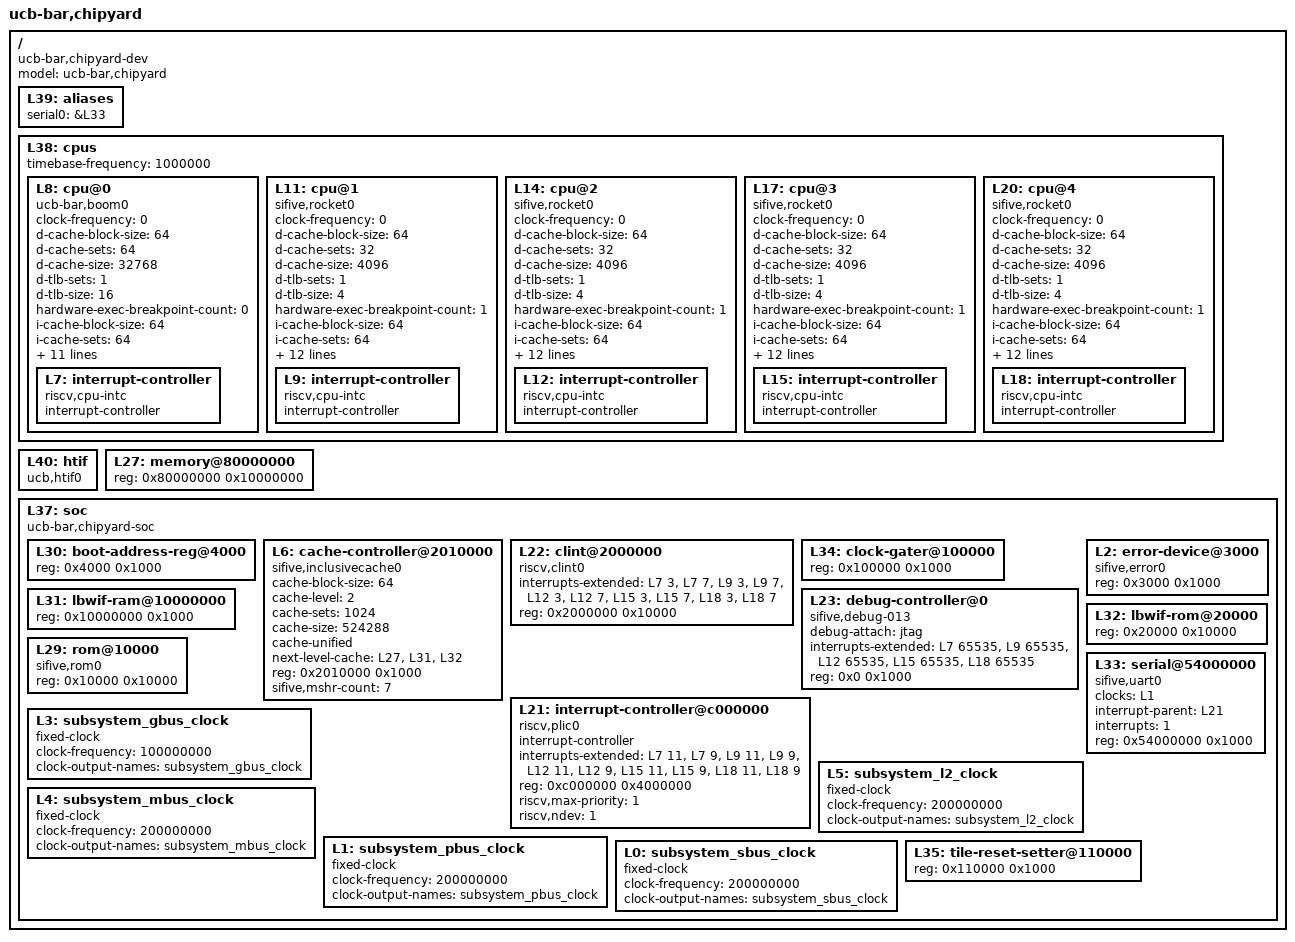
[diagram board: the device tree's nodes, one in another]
/dts-v1/;

/ {
	#address-cells = <1>;
	#size-cells = <1>;
	compatible = "ucb-bar,chipyard-dev";
	model = "ucb-bar,chipyard";
	L39: aliases {
		serial0 = &L33;
	};
	L38: cpus {
		#address-cells = <1>;
		#size-cells = <0>;
		timebase-frequency = <1000000>;
		L8: cpu@0 {
			clock-frequency = <0>;
			compatible = "ucb-bar,boom0", "riscv";
			d-cache-block-size = <64>;
			d-cache-sets = <64>;
			d-cache-size = <32768>;
			d-tlb-sets = <1>;
			d-tlb-size = <16>;
			device_type = "cpu";
			hardware-exec-breakpoint-count = <0>;
			i-cache-block-size = <64>;
			i-cache-sets = <64>;
			i-cache-size = <32768>;
			i-tlb-sets = <1>;
			i-tlb-size = <32>;
			mmu-type = "riscv,sv39";
			next-level-cache = <&L6>;
			reg = <0x0>;
			riscv,isa = "rv64imafdcZicsr_Zifencei_Zihpm";
			riscv,pmpgranularity = <4>;
			riscv,pmpregions = <8>;
			status = "okay";
			timebase-frequency = <1000000>;
			tlb-split;
			L7: interrupt-controller {
				#interrupt-cells = <1>;
				compatible = "riscv,cpu-intc";
				interrupt-controller;
			};
		};
		L11: cpu@1 {
			clock-frequency = <0>;
			compatible = "sifive,rocket0", "riscv";
			d-cache-block-size = <64>;
			d-cache-sets = <32>;
			d-cache-size = <4096>;
			d-tlb-sets = <1>;
			d-tlb-size = <4>;
			device_type = "cpu";
			hardware-exec-breakpoint-count = <1>;
			i-cache-block-size = <64>;
			i-cache-sets = <64>;
			i-cache-size = <32768>;
			i-tlb-sets = <1>;
			i-tlb-size = <32>;
			mmu-type = "riscv,sv39";
			next-level-cache = <&L6>;
			reg = <0x1>;
			riscv,isa = "rv64imafdcZicsr_Zifencei_Zihpm_Xrocket";
			riscv,pmpgranularity = <4>;
			riscv,pmpregions = <8>;
			status = "okay";
			timebase-frequency = <1000000>;
			tlb-split;
			L9: interrupt-controller {
				#interrupt-cells = <1>;
				compatible = "riscv,cpu-intc";
				interrupt-controller;
			};
		};
		L14: cpu@2 {
			clock-frequency = <0>;
			compatible = "sifive,rocket0", "riscv";
			d-cache-block-size = <64>;
			d-cache-sets = <32>;
			d-cache-size = <4096>;
			d-tlb-sets = <1>;
			d-tlb-size = <4>;
			device_type = "cpu";
			hardware-exec-breakpoint-count = <1>;
			i-cache-block-size = <64>;
			i-cache-sets = <64>;
			i-cache-size = <32768>;
			i-tlb-sets = <1>;
			i-tlb-size = <32>;
			mmu-type = "riscv,sv39";
			next-level-cache = <&L6>;
			reg = <0x2>;
			riscv,isa = "rv64imafdcZicsr_Zifencei_Zihpm_Xrocket";
			riscv,pmpgranularity = <4>;
			riscv,pmpregions = <8>;
			status = "okay";
			timebase-frequency = <1000000>;
			tlb-split;
			L12: interrupt-controller {
				#interrupt-cells = <1>;
				compatible = "riscv,cpu-intc";
				interrupt-controller;
			};
		};
		L17: cpu@3 {
			clock-frequency = <0>;
			compatible = "sifive,rocket0", "riscv";
			d-cache-block-size = <64>;
			d-cache-sets = <32>;
			d-cache-size = <4096>;
			d-tlb-sets = <1>;
			d-tlb-size = <4>;
			device_type = "cpu";
			hardware-exec-breakpoint-count = <1>;
			i-cache-block-size = <64>;
			i-cache-sets = <64>;
			i-cache-size = <32768>;
			i-tlb-sets = <1>;
			i-tlb-size = <32>;
			mmu-type = "riscv,sv39";
			next-level-cache = <&L6>;
			reg = <0x3>;
			riscv,isa = "rv64imafdcZicsr_Zifencei_Zihpm_Xrocket";
			riscv,pmpgranularity = <4>;
			riscv,pmpregions = <8>;
			status = "okay";
			timebase-frequency = <1000000>;
			tlb-split;
			L15: interrupt-controller {
				#interrupt-cells = <1>;
				compatible = "riscv,cpu-intc";
				interrupt-controller;
			};
		};
		L20: cpu@4 {
			clock-frequency = <0>;
			compatible = "sifive,rocket0", "riscv";
			d-cache-block-size = <64>;
			d-cache-sets = <32>;
			d-cache-size = <4096>;
			d-tlb-sets = <1>;
			d-tlb-size = <4>;
			device_type = "cpu";
			hardware-exec-breakpoint-count = <1>;
			i-cache-block-size = <64>;
			i-cache-sets = <64>;
			i-cache-size = <32768>;
			i-tlb-sets = <1>;
			i-tlb-size = <32>;
			mmu-type = "riscv,sv39";
			next-level-cache = <&L6>;
			reg = <0x4>;
			riscv,isa = "rv64imafdcZicsr_Zifencei_Zihpm_Xrocket";
			riscv,pmpgranularity = <4>;
			riscv,pmpregions = <8>;
			status = "okay";
			timebase-frequency = <1000000>;
			tlb-split;
			L18: interrupt-controller {
				#interrupt-cells = <1>;
				compatible = "riscv,cpu-intc";
				interrupt-controller;
			};
		};
	};
	L40: htif {
		compatible = "ucb,htif0";
	};
	L27: memory@80000000 {
		device_type = "memory";
		reg = <0x80000000 0x10000000>;
	};
	L37: soc {
		#address-cells = <1>;
		#size-cells = <1>;
		compatible = "ucb-bar,chipyard-soc", "simple-bus";
		ranges;
		L30: boot-address-reg@4000 {
			reg = <0x4000 0x1000>;
			reg-names = "control";
		};
		L6: cache-controller@2010000 {
			cache-block-size = <64>;
			cache-level = <2>;
			cache-sets = <1024>;
			cache-size = <524288>;
			cache-unified;
			compatible = "sifive,inclusivecache0", "cache";
			next-level-cache = <&L27 &L31 &L32>;
			reg = <0x2010000 0x1000>;
			reg-names = "control";
			sifive,mshr-count = <7>;
		};
		L22: clint@2000000 {
			compatible = "riscv,clint0";
			interrupts-extended = <&L7 3 &L7 7 &L9 3 &L9 7 &L12 3 &L12 7 &L15 3 &L15 7 &L18 3 &L18 7>;
			reg = <0x2000000 0x10000>;
			reg-names = "control";
		};
		L34: clock-gater@100000 {
			reg = <0x100000 0x1000>;
			reg-names = "control";
		};
		L23: debug-controller@0 {
			compatible = "sifive,debug-013", "riscv,debug-013";
			debug-attach = "jtag";
			interrupts-extended = <&L7 65535 &L9 65535 &L12 65535 &L15 65535 &L18 65535>;
			reg = <0x0 0x1000>;
			reg-names = "control";
		};
		L2: error-device@3000 {
			compatible = "sifive,error0";
			reg = <0x3000 0x1000>;
		};
		L21: interrupt-controller@c000000 {
			#interrupt-cells = <1>;
			compatible = "riscv,plic0";
			interrupt-controller;
			interrupts-extended = <&L7 11 &L7 9 &L9 11 &L9 9 &L12 11 &L12 9 &L15 11 &L15 9 &L18 11 &L18 9>;
			reg = <0xc000000 0x4000000>;
			reg-names = "control";
			riscv,max-priority = <1>;
			riscv,ndev = <1>;
		};
		L31: lbwif-ram@10000000 {
			reg = <0x10000000 0x1000>;
		};
		L32: lbwif-rom@20000 {
			reg = <0x20000 0x10000>;
		};
		L29: rom@10000 {
			compatible = "sifive,rom0";
			reg = <0x10000 0x10000>;
			reg-names = "mem";
		};
		L33: serial@54000000 {
			clocks = <&L1>;
			compatible = "sifive,uart0";
			interrupt-parent = <&L21>;
			interrupts = <1>;
			reg = <0x54000000 0x1000>;
			reg-names = "control";
		};
		L3: subsystem_gbus_clock {
			#clock-cells = <0>;
			clock-frequency = <100000000>;
			clock-output-names = "subsystem_gbus_clock";
			compatible = "fixed-clock";
		};
		L5: subsystem_l2_clock {
			#clock-cells = <0>;
			clock-frequency = <200000000>;
			clock-output-names = "subsystem_l2_clock";
			compatible = "fixed-clock";
		};
		L4: subsystem_mbus_clock {
			#clock-cells = <0>;
			clock-frequency = <200000000>;
			clock-output-names = "subsystem_mbus_clock";
			compatible = "fixed-clock";
		};
		L1: subsystem_pbus_clock {
			#clock-cells = <0>;
			clock-frequency = <200000000>;
			clock-output-names = "subsystem_pbus_clock";
			compatible = "fixed-clock";
		};
		L0: subsystem_sbus_clock {
			#clock-cells = <0>;
			clock-frequency = <200000000>;
			clock-output-names = "subsystem_sbus_clock";
			compatible = "fixed-clock";
		};
		L35: tile-reset-setter@110000 {
			reg = <0x110000 0x1000>;
			reg-names = "control";
		};
	};
};
